VERSION ""

NS_ :

BS_:

BU_: XXX

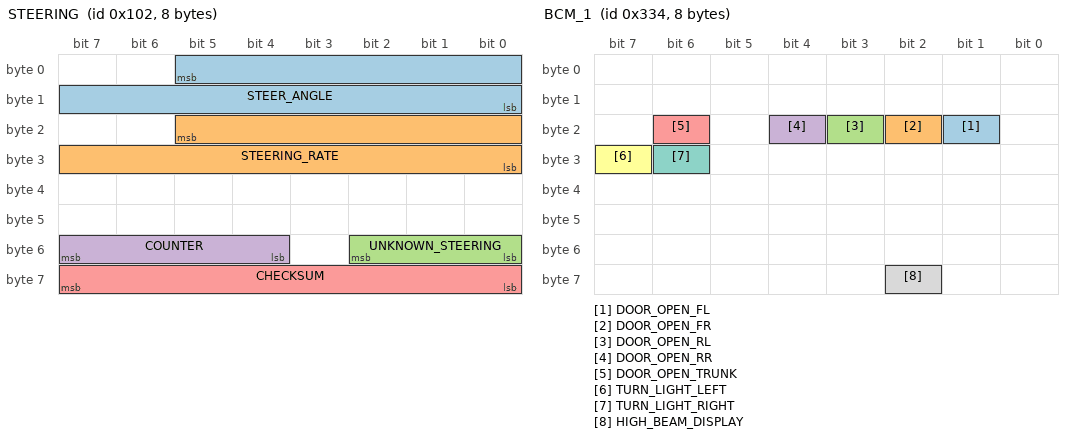
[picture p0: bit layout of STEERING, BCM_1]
BO_ 258 STEERING: 8 XXX
 SG_ STEER_ANGLE : 5|14@0+ (0.5,-2048) [-2048|2047] "deg" XXX
 SG_ STEERING_RATE : 21|14@0+ (0.5,-2048) [-2048|2047] "deg/s" XXX
 SG_ UNKNOWN_STEERING : 50|3@0+ (1,0) [0|15] "" XXX
 SG_ COUNTER : 55|4@0+ (1,0) [0|15] "" XXX
 SG_ CHECKSUM : 63|8@0+ (1,0) [0|255] "" XXX

BO_ 514 SPEED_1: 8 XXX
 SG_ SPEED_LEFT : 7|12@0+ (0.071028,0) [0|65535] "m/s" XXX
 SG_ SPEED_RIGHT : 23|12@0+ (0.071028,0) [0|1023] "m/s" XXX

BO_ 653 BRAKE_MODULE: 2 XXX
 SG_ BRAKE_PRESSURE : 15|8@0+ (1,0) [0|255] "" XXX
 SG_ BRAKE_PRESSED : 4|1@0+ (1,0) [0|4] "" XXX

BO_ 820 BCM_1: 8 XXX
 SG_ DOOR_OPEN_FL : 17|1@0+ (1,0) [0|1] "" XXX
 SG_ DOOR_OPEN_FR : 18|1@0+ (1,0) [0|1] "" XXX
 SG_ DOOR_OPEN_RL : 19|1@0+ (1,0) [0|1] "" XXX
 SG_ DOOR_OPEN_RR : 20|1@0+ (1,0) [0|1] "" XXX
 SG_ DOOR_OPEN_TRUNK : 22|1@0+ (1,0) [0|1] "" XXX
 SG_ TURN_LIGHT_LEFT : 31|1@0+ (1,0) [0|1] "" XXX
 SG_ TURN_LIGHT_RIGHT : 30|1@0+ (1,0) [0|1] "" XXX
 SG_ HIGH_BEAM_DISPLAY : 58|1@0+ (1,0) [0|1] "" XXX

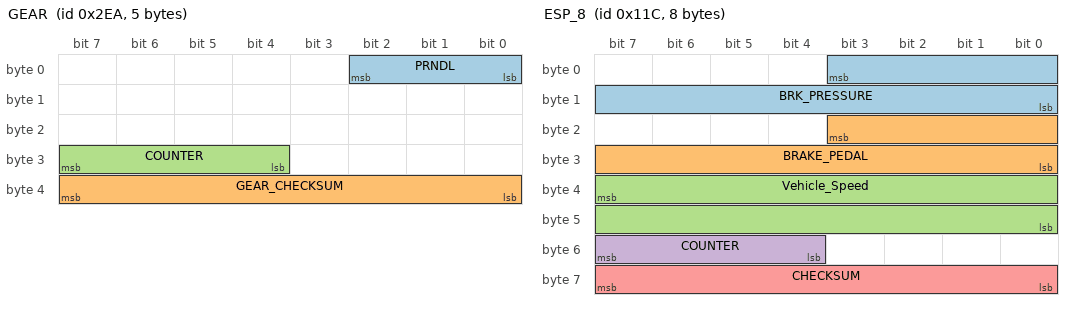
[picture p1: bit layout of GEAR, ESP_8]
BO_ 746 GEAR: 5 XXX
 SG_ PRNDL : 2|3@0+ (1,0) [0|7] "" XXX
 SG_ GEAR_CHECKSUM : 39|8@0+ (1,0) [0|255] "" XXX
 SG_ COUNTER : 31|4@0+ (1,0) [0|15] "" XXX

BO_ 284 ESP_8: 8 XXX
 SG_ BRK_PRESSURE : 3|12@0+ (1,0) [0|1] "" XXX
 SG_ BRAKE_PEDAL : 19|12@0+ (1,0) [0|1] "" XXX
 SG_ Vehicle_Speed : 39|16@0+ (0.0078125,0) [0|511.984375] "km/h" XXX
 SG_ COUNTER : 55|4@0+ (1,0) [0|15] "" XXX
 SG_ CHECKSUM : 63|8@0+ (1,0) [0|255] "" XXX

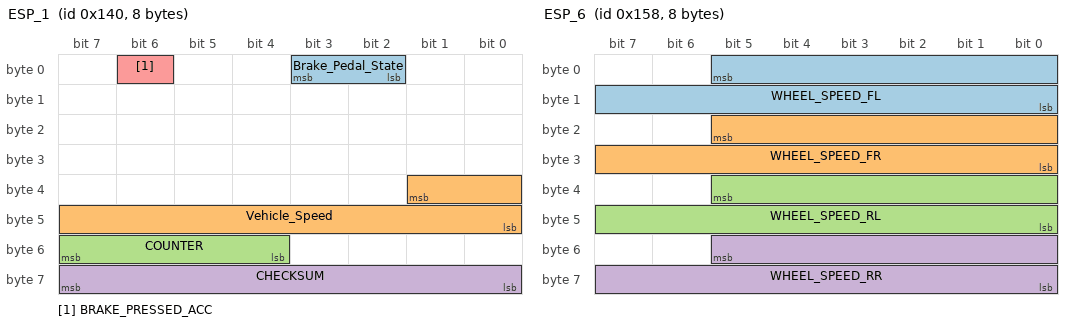
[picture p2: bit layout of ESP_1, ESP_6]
BO_ 320 ESP_1: 8 XXX
 SG_ Brake_Pedal_State : 2|2@1+ (1,0) [0|0] "" XXX
 SG_ Vehicle_Speed : 33|10@0+ (0.5,0) [0|511] "km/h" XXX
 SG_ COUNTER : 55|4@0+ (1,0) [0|15] "" XXX
 SG_ CHECKSUM : 63|8@0+ (1,0) [0|255] "" XXX
 SG_ BRAKE_PRESSED_ACC : 6|1@0+ (1,0) [0|3] "" XXX

BO_ 736 TRIP: 8 XXX
 SG_ COUNTER : 7|16@0+ (1,0) [0|65535] "Meters" XXX
 SG_ COUNTER_2 : 23|16@0+ (1,0) [0|65535] "Meters" XXX

BO_ 344 ESP_6: 8 XXX
 SG_ WHEEL_SPEED_FL : 5|14@0+ (0.5,0) [0|8191] "rpm" XXX
 SG_ WHEEL_SPEED_FR : 21|14@0+ (0.5,0) [0|8191] "rpm" XXX
 SG_ WHEEL_SPEED_RL : 37|14@0+ (0.5,0) [0|8191] "rpm" XXX
 SG_ WHEEL_SPEED_RR : 53|14@0+ (0.5,0) [0|8191] "rpm" XXX

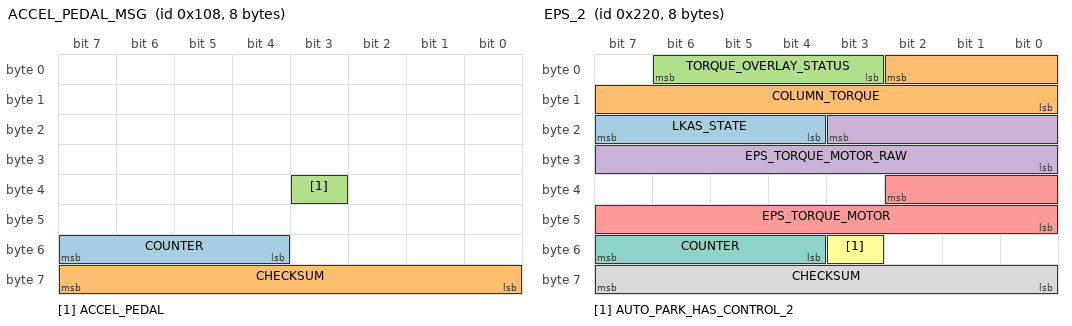
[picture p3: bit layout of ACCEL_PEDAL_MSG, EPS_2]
BO_ 264 ACCEL_PEDAL_MSG: 8 XXX
 SG_ COUNTER : 55|4@0+ (1,0) [0|15] "" XXX
 SG_ CHECKSUM : 63|8@0+ (1,0) [0|255] "" XXX
 SG_ ACCEL_PEDAL : 35|1@0+ (1,0) [0|1] "" XXX

BO_ 464 ORC_1: 8 XXX
 SG_ SEATBELT_DRIVER_UNLATCHED : 13|1@0+ (1,0) [0|1] "" XXX

BO_ 544 EPS_2: 8 XXX
 SG_ LKAS_STATE : 23|4@0+ (1,0) [0|15] "" XXX
 SG_ COLUMN_TORQUE : 2|11@0+ (1,-1024) [-1024|1023] "" XXX
 SG_ TORQUE_OVERLAY_STATUS : 6|4@0+ (1,0) [0|15] "" XXX
 SG_ EPS_TORQUE_MOTOR_RAW : 19|12@0+ (1,-2048) [-2048|2047] "" XXX
 SG_ EPS_TORQUE_MOTOR : 34|11@0+ (1,-1024) [-1024|1023] "" XXX
 SG_ AUTO_PARK_HAS_CONTROL_2 : 51|1@0+ (1,0) [0|1] "" XXX
 SG_ COUNTER : 55|4@0+ (1,0) [0|15] "" XXX
 SG_ CHECKSUM : 63|8@0+ (1,0) [0|255] "" XXX

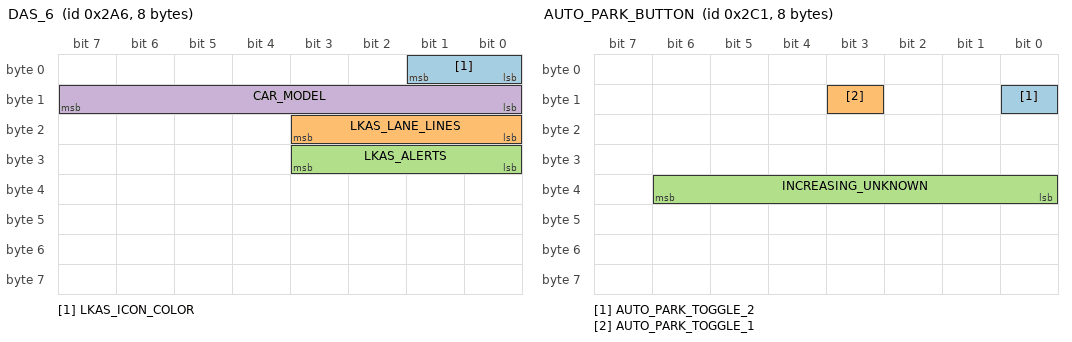
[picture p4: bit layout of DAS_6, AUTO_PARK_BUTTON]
BO_ 678 DAS_6: 8 XXX
 SG_ LKAS_ICON_COLOR : 1|2@0+ (1,0) [0|3] "" XXX
 SG_ LKAS_LANE_LINES : 19|4@0+ (1,0) [0|1] "" XXX
 SG_ LKAS_ALERTS : 27|4@0+ (1,0) [0|1] "" XXX
 SG_ CAR_MODEL : 15|8@0+ (1,0) [0|255] "" XXX

BO_ 705 AUTO_PARK_BUTTON: 8 XXX
 SG_ AUTO_PARK_TOGGLE_2 : 8|1@0+ (1,0) [0|1] "" XXX
 SG_ AUTO_PARK_TOGGLE_1 : 11|1@0+ (1,0) [0|1] "" XXX
 SG_ INCREASING_UNKNOWN : 38|7@0+ (1,0) [0|15] "" XXX

BO_ 720 BLIND_SPOT_WARNINGS: 6 XXX
 SG_ BLIND_SPOT_RIGHT : 5|1@0+ (1,0) [0|1] "" XXX
 SG_ BLIND_SPOT_LEFT : 2|1@0+ (1,0) [0|1] "" XXX

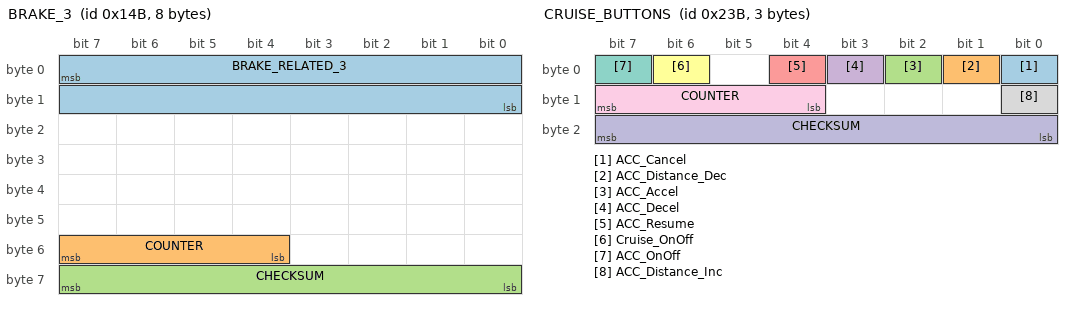
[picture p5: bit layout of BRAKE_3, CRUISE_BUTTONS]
BO_ 331 BRAKE_3: 8 XXX
 SG_ BRAKE_RELATED_3 : 7|16@0+ (1,0) [0|65535] "" XXX
 SG_ COUNTER : 55|4@0+ (1,0) [0|15] "" XXX
 SG_ CHECKSUM : 63|8@0+ (1,0) [0|255] "" XXX

BO_ 571 CRUISE_BUTTONS: 3 XXX
 SG_ ACC_Cancel : 0|1@1+ (1,0) [0|0] "" XXX
 SG_ ACC_Distance_Dec : 1|1@1+ (1,0) [0|0] "" XXX
 SG_ ACC_Accel : 2|1@1+ (1,0) [0|0] "" XXX
 SG_ ACC_Decel : 3|1@1+ (1,0) [0|0] "" XXX
 SG_ ACC_Resume : 4|1@0+ (1,0) [0|1] "" XXX
 SG_ Cruise_OnOff : 6|1@1+ (1,0) [0|0] "" XXX
 SG_ ACC_OnOff : 7|1@1+ (1,0) [0|0] "" XXX
 SG_ ACC_Distance_Inc : 8|1@1+ (1,0) [0|0] "" XXX
 SG_ COUNTER : 15|4@0+ (1,0) [0|15] "" XXX
 SG_ CHECKSUM : 23|8@0+ (1,0) [0|255] "" XXX

BO_ 816 TRACTION_BUTTON: 8 XXX
 SG_ TRACTION_OFF : 19|1@0+ (1,0) [0|3] "" XXX
 SG_ TOGGLE_PARKSENSE : 52|1@0+ (1,0) [0|3] "" XXX

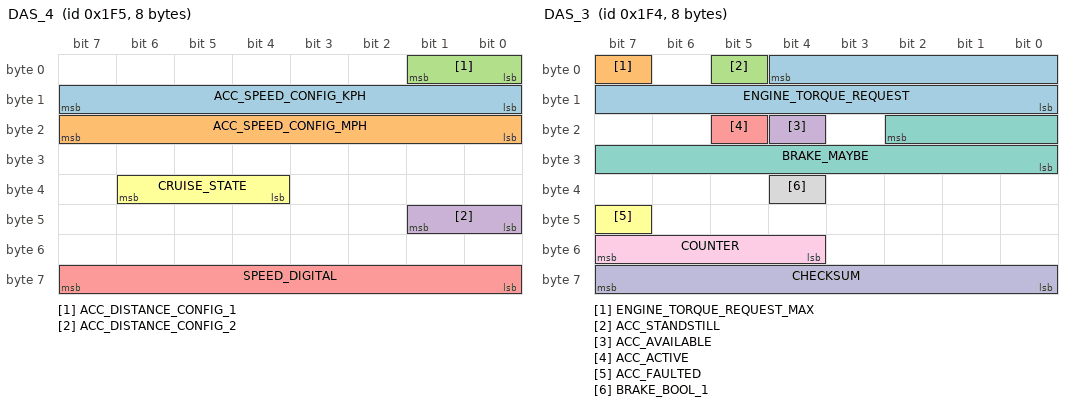
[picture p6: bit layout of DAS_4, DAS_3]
BO_ 501 DAS_4: 8 XXX
 SG_ ACC_SPEED_CONFIG_KPH : 15|8@0+ (1,0) [0|3] "km/h" XXX
 SG_ ACC_SPEED_CONFIG_MPH : 23|8@0+ (1,0) [0|3] "mph" XXX
 SG_ ACC_DISTANCE_CONFIG_1 : 1|2@0+ (1,0) [0|3] "" XXX
 SG_ ACC_DISTANCE_CONFIG_2 : 41|2@0+ (1,0) [0|3] "" XXX
 SG_ SPEED_DIGITAL : 63|8@0+ (1,0) [0|255] "mph" XXX
 SG_ CRUISE_STATE : 38|3@0+ (1,0) [0|7] "" XXX

BO_ 500 DAS_3: 8 XXX
 SG_ ENGINE_TORQUE_REQUEST : 4|13@0+ (0.25,-500) [-500|1547.5] "Nm" XXX
 SG_ ENGINE_TORQUE_REQUEST_MAX : 7|1@0+ (1,0) [0|1] "" XXX
 SG_ ACC_STANDSTILL : 5|1@0+ (1,0) [0|1] ""  XXX
 SG_ ACC_AVAILABLE : 20|1@0+ (1,0) [0|1] "" XXX
 SG_ ACC_ACTIVE : 21|1@0+ (1,0) [0|1] "" XXX
 SG_ ACC_FAULTED : 47|1@0+ (1,0) [0|1] "" XXX
 SG_ BRAKE_MAYBE : 18|11@0+ (1,0) [0|255] "" XXX
 SG_ BRAKE_BOOL_1 : 36|1@0+ (1,0) [0|3] "" XXX
 SG_ COUNTER : 55|4@0+ (1,0) [0|15] "" XXX
 SG_ CHECKSUM : 63|8@0+ (1,0) [0|255] "" XXX

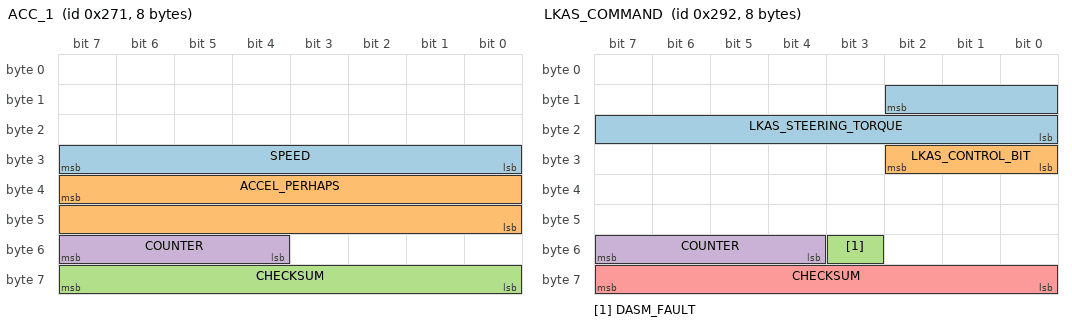
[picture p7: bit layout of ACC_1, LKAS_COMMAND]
BO_ 625 ACC_1: 8 XXX
 SG_ SPEED : 31|8@0+ (1,0) [0|255] "km/h" XXX
 SG_ ACCEL_PERHAPS : 39|16@0+ (1,0) [0|255] "" XXX
 SG_ CHECKSUM : 63|8@0+ (1,0) [0|255] "" XXX
 SG_ COUNTER : 55|4@0+ (1,0) [0|15] "" XXX

BO_ 658 LKAS_COMMAND: 8 XXX
 SG_ LKAS_STEERING_TORQUE : 10|11@0+ (1,-1024) [0|1] "" XXX
 SG_ LKAS_CONTROL_BIT : 24|3@1+ (1,0) [0|1] "" XXX
 SG_ DASM_FAULT : 51|1@0+ (1,0) [0|1] "" XXX
 SG_ COUNTER : 55|4@0+ (1,0) [0|15] "" XXX
 SG_ CHECKSUM : 63|8@0+ (1,0) [0|255] "" XXX

CM_ SG_ 258 UNKNOWN_STEERING "never goes above 4. see if human-applied torque";
CM_ SG_ 258 STEER_ANGLE "positive is left (counter-clockwise)";
CM_ SG_ 514 SPEED_LEFT "TODO find upper limit";
CM_ SG_ 653 BRAKE_PRESSURE "max seems to be 148";
CM_ SG_ 820 TURN_LIGHT_LEFT "oscillates with the light blinking";
CM_ SG_ 820 TURN_LIGHT_RIGHT "hazard blinks both right and left lights";
CM_ SG_ 746 PRNDL "5=L, 4=D, 3=N, 2=R, 1=P";
CM_ SG_ 746 GEAR_CHECKSUM "different than the LKAS checksum. unknown non-simple algorithm. just build a lookup table for it.";
CM_ SG_ 284 SPEED_RELATED_1 "Another Speed Signal, Maybe RPMs?";
CM_ SG_ 284 BRAKE_RELATED_1_1 "Correlates with braking";
CM_ SG_ 320 BRAKE_PRESSED_2 "Value is 5 when brake is pressed by human, 1 when ACC brake";
CM_ SG_ 320 BRAKE_PRESSED_ACC "set when ACC brakes";
CM_ SG_ 792 TURN_SIGNALS "1=Left, 2=Right";
CM_ SG_ 792 HIGH_BEAM_FLASH "use this for genericToggle";
CM_ SG_ 264 ACCEL_PEDAL "not in ACC so seems to be actual pedal. Use for gasPressed";
CM_ SG_ 544 LKAS_STATE "2 when autopark has control, 8 when is actuatable by lkas, 4 when there is a fault";
CM_ SG_ 544 TORQUE_MOTOR_RAW "has larger range than TORQUE_MOTOR but ut seems biased";
CM_ SG_ 658 LKAS_CONTROL_BIT "0=IDLE, 1=HAS 2=LKAS 3=ABSD, 4=TJA, 7=SNA";
CM_ SG_ 678 LKAS_ICON_COLOR "3 is yellow, 2 is green, 1 is white, 0 is null";
CM_ SG_ 678 LKAS_LANE_LINES "0x01 transparent lines, 0x02 left white, 0x03 right white, 0x04 left yellow with car on top, 0x05 left yellow with car on top, 0x06 both white, 0x07 left yellow, 0x08 left yellow right white, 0x09 right yellow, 0x0a right yellow left white, 0x0b left yellow with car on top right white, 0x0c right yellow with car on top left white, (0x00, 0x0d, 0x0e, 0x0f) null";
CM_ SG_ 678 LKAS_ALERTS "(0x01, 0x02) lane sense off, (0x03, 0x04, 0x06) place hands on steering wheel, 0x07 lane departure detected + place hands on steering wheel, (0x08, 0x09) lane sense unavailable + clean front windshield, 0x0b lane sense and auto high beam unavailable + clean front windshield, 0x0c lane sense unavailable + service required, (0x00, 0x05, 0x0a, 0x0d, 0x0e, 0x0f) null";
CM_ SG_ 705 AUTO_PARK_TOGGLE_1 "set briefly when turning on or off self-parking";
CM_ SG_ 705 INCREASING_UNKNOWN "sometimes decreasing";
CM_ SG_ 671 AUTO_PARK_CMD "Request Appears to be in NM";
CM_ SG_ 671 AUTO_PARK_STATUS "1 = IDLE / NO REQUEST 9 = START REQUEST 10 = REQUEST MODE 11 = REQUEST MODE";
CM_ SG_ 784 INCREASING_UNKNOWN "perhaps distance traveled";
CM_ SG_ 826 AUTO_PARK_GEAR_1 "Reverse=0, Forward=f";
CM_ SG_ 826 AUTO_PARK_GEAR_2 "Reverse=0, Forward=f";
CM_ SG_ 826 AUTO_PARK_GEAR_3 "Reverse=0, Forward=f";
CM_ SG_ 332 STEER_ANGLE_2 "slightly lags the other steer_angle signal. also more noisy.";
CM_ SG_ 720 BLIND_SPOT_RIGHT "yellow triangle alert on side view mirror when a car is in your blind spot";
CM_ SG_ 608 PARKSENSE_DISABLED "set if parksense is disabled";
CM_ SG_ 729 LKAS_STATUS_OK "Set to 0x0820 when LKAS system is plugged in.";
CM_ SG_ 288 UNKNOWN_CHECKSUM "not the LKAS checksum";
CM_ SG_ 288 GAS_ENGINE_RPM_MAYBE "lags acceleration, perhaps gas engine";
CM_ SG_ 257 ENERGY_OR_RPM "perhaps energy consumption or RPMs";
CM_ SG_ 571 CHECKSUM "standard checksum";
CM_ SG_ 825 BEEP_339 "sent every 0.5s. 0050 is no beep. To beep send 4355 or 4155. Used by ParkSense warning.";
CM_ SG_ 270 ELECTRIC_MOTOR "0x7fff indicates electric motor not in use";
CM_ SG_ 291 ENERGY_GAIN_LOSS "unsure what this actually is";
CM_ SG_ 291 ENERGY_SMOOTHER_CURVE "unsure what it is, but smoother";
CM_ SG_ 308 ACCEL_134 "only set when human presses accel pedal";
CM_ SG_ 532 NOISY_SLOWLY_DECREASING "perhaps battery but do not know";
CM_ SG_ 816 TRACTION_OFF "set when traction off button is enabled";
CM_ SG_ 816 TOGGLE_PARKSENSE "sending 3000071ec0ff9000 enables or disables parksense";
CM_ SG_ 324 SPEED_2 "signal is approx half other speeds";
CM_ SG_ 501 ACC_SPEED_CONFIG_KPH "speed configured for ACC";
CM_ SG_ 501 ACC_SPEED_CONFIG_MPH "speed configured for ACC";
CM_ SG_ 500 BRAKE_MAYBE "2046 in non-ACC and non-decel. Signal on deceleration. 818 for already stopped break.";
CM_ SG_ 500 BRAKE_BOOL_1 "set to 1 when ACC decel. 0 on non-ACC and accel.";
CM_ SG_ 501 CRUISE_STATE "may just be an icon, but seems to indicate different cruise modes: ACC and Non-ACC and engaged state for both.";
CM_ SG_ 625 SPEED "zero on non-acc drives";
CM_ SG_ 625 ACCEL_PERHAPS "set to 7767 on non-ACC drives. ACC drive 40k is constant speed, 42k is accelerating";
CM_ SG_ 268 BRAKE_PERHAPS "triggers only on ACC braking";
CM_ SG_ 384 NEW_SIGNAL_1 "set in ACC gas driving. not set in electric human. not sure about gas human driving.";

VAL_ 501 CRUISE_STATE 0 "Off" 1 "CC On" 2 "CC Engaged" 3 "ACC On" 4 "ACC Engaged";
VAL_ 746 PRNDL 5 "L" 4 "D" 3 "N" 2 "R" 1 "P";
VAL_ 792 TURN_SIGNALS 2 "Right" 1 "Left";
